# HDSC_HC32F460PEHB register map
Vendor: HDSC Co.,Ltd.; Series: ARMCM4; File version: 1.0
CPU: CM4 r0p1, little endian, MPU, FPU, 4 interrupt priority bits
Registers are 32-bit, read-write, reset 0x0 unless marked. A register's access mark holds for its fields unless they carry their own. Offsets are from the block's base; [hi:lo] are bit positions; 'fields as' and 'values as' point back to an identical list.

## SRAMC
Base 0x40050800
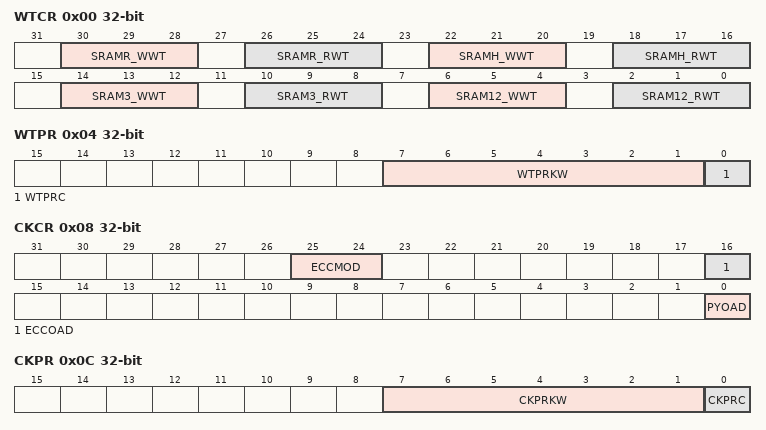
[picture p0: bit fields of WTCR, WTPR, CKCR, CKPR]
0x00 WTCR
  [30:28] SRAMR_WWT, [26:24] SRAMR_RWT, [22:20] SRAMH_WWT, [18:16] SRAMH_RWT, [14:12] SRAM3_WWT, [10:8] SRAM3_RWT, [6:4] SRAM12_WWT, [2:0] SRAM12_RWT
0x04 WTPR
  [7:1] WTPRKW, [0] WTPRC
0x08 CKCR
  [25:24] ECCMOD, [16] ECCOAD, [0] PYOAD
0x0C CKPR
  [7:1] CKPRKW, [0] CKPRC
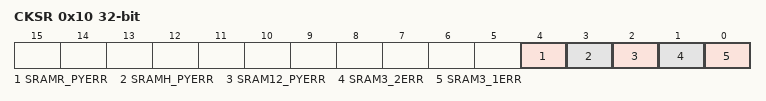
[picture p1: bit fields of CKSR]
0x10 CKSR
  [4] SRAMR_PYERR, [3] SRAMH_PYERR, [2] SRAM12_PYERR, [1] SRAM3_2ERR, [0] SRAM3_1ERR

## SWDT
Base 0x40049400
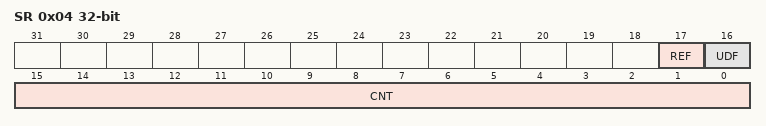
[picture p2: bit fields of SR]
0x04 SR ro
  [17] REF rw, [16] UDF rw, [15:0] CNT
0x08 RR ro
  [15:0] RF

## TMR01 — desc TMR0
Base 0x40024000
Same registers: TMR02 0x40024400
0x00 CNTAR
  [15:0] CNTA
0x04 CNTBR
  [15:0] CNTB
0x08 CMPAR reset 0xFFFF
  [15:0] CMPA
0x0C CMPBR reset 0xFFFF
  [15:0] CMPB
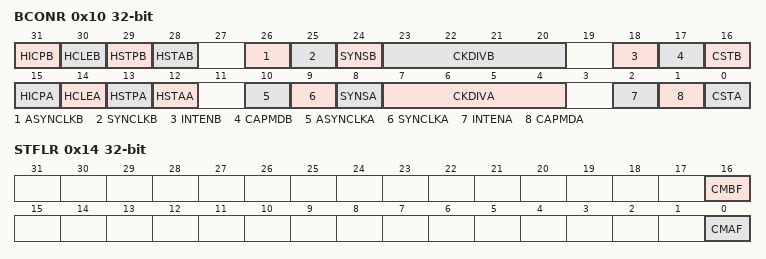
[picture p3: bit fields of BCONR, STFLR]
0x10 BCONR
  [31] HICPB, [30] HCLEB, [29] HSTPB, [28] HSTAB, [26] ASYNCLKB, [25] SYNCLKB, [24] SYNSB, [23:20] CKDIVB, [18] INTENB, [17] CAPMDB, [16] CSTB, [15] HICPA, [14] HCLEA, [13] HSTPA, [12] HSTAA, [10] ASYNCLKA, [9] SYNCLKA, [8] SYNSA, [7:4] CKDIVA, [2] INTENA, [1] CAPMDA, [0] CSTA
0x14 STFLR
  [16] CMBF, [0] CMAF

## TMR41 — desc TMR4
Base 0x40017000
Same registers: TMR42 0x40024800, TMR43 0x40024C00
0x02 OCCRUH 16-bit
0x06 OCCRUL 16-bit
0x0A OCCRVH 16-bit
0x0E OCCRVL 16-bit
0x12 OCCRWH 16-bit
0x16 OCCRWL 16-bit
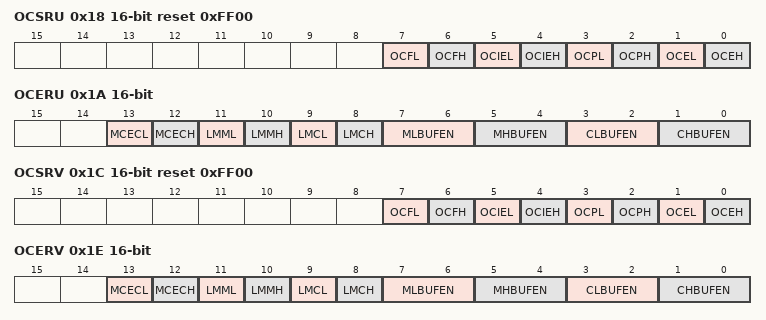
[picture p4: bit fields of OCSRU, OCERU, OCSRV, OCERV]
0x18 OCSRU 16-bit reset 0xFF00
  [7] OCFL, [6] OCFH, [5] OCIEL, [4] OCIEH, [3] OCPL, [2] OCPH, [1] OCEL, [0] OCEH
0x1A OCERU 16-bit
  [13] MCECL, [12] MCECH, [11] LMML, [10] LMMH, [9] LMCL, [8] LMCH, [7:6] MLBUFEN, [5:4] MHBUFEN, [3:2] CLBUFEN, [1:0] CHBUFEN
0x1C OCSRV 16-bit reset 0xFF00
  fields as OCSRU
0x1E OCERV 16-bit
  fields as OCERU
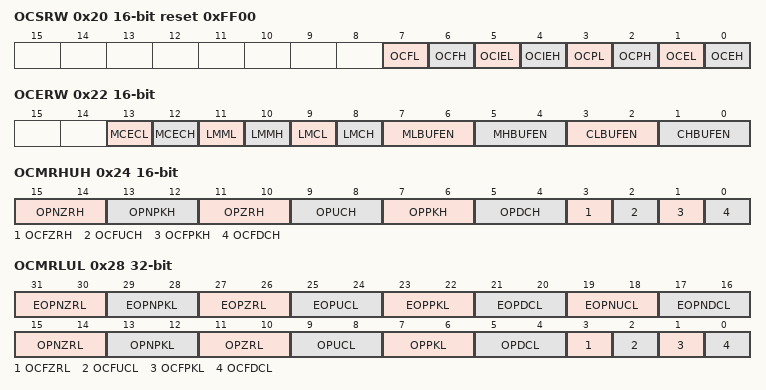
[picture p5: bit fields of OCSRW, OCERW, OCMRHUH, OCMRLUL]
0x20 OCSRW 16-bit reset 0xFF00
  fields as OCSRU
0x22 OCERW 16-bit
  fields as OCERU
0x24 OCMRHUH 16-bit
  [15:14] OPNZRH, [13:12] OPNPKH, [11:10] OPZRH, [9:8] OPUCH, [7:6] OPPKH, [5:4] OPDCH, [3] OCFZRH, [2] OCFUCH, [1] OCFPKH, [0] OCFDCH
0x28 OCMRLUL
  [31:30] EOPNZRL, [29:28] EOPNPKL, [27:26] EOPZRL, [25:24] EOPUCL, [23:22] EOPPKL, [21:20] EOPDCL, [19:18] EOPNUCL, [17:16] EOPNDCL, [15:14] OPNZRL, [13:12] OPNPKL, [11:10] OPZRL, [9:8] OPUCL, [7:6] OPPKL, [5:4] OPDCL, [3] OCFZRL, [2] OCFUCL, [1] OCFPKL, [0] OCFDCL
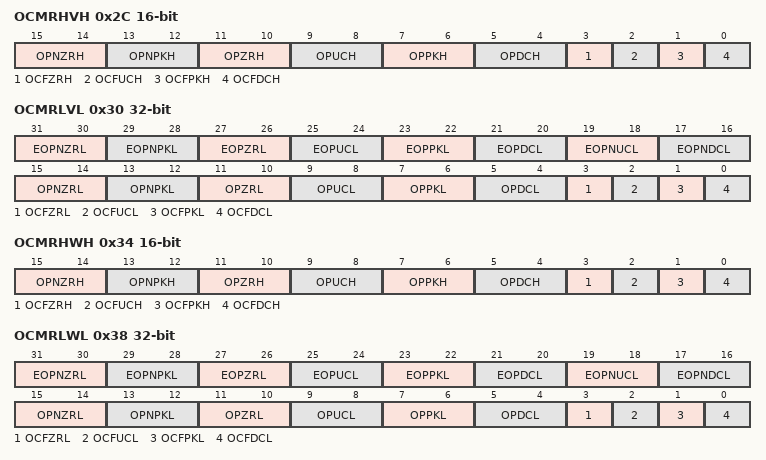
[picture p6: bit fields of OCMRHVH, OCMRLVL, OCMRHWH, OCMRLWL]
0x2C OCMRHVH 16-bit
  fields as OCMRHUH
0x30 OCMRLVL
  fields as OCMRLUL
0x34 OCMRHWH 16-bit
  fields as OCMRHUH
0x38 OCMRLWL
  fields as OCMRLUL
0x42 CPSR 16-bit reset 0xFFFF
0x46 CNTR 16-bit
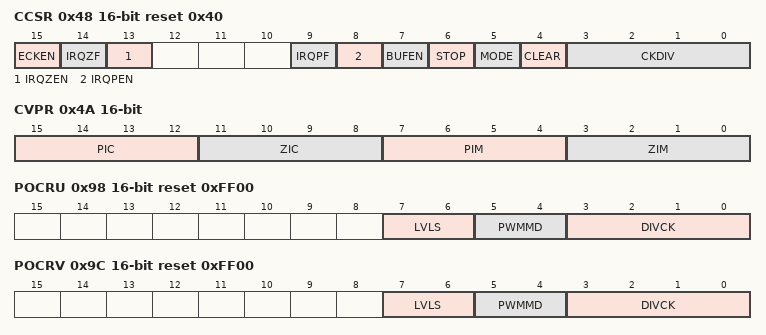
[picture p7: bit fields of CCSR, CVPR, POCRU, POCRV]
0x48 CCSR 16-bit reset 0x40
  [15] ECKEN, [14] IRQZF, [13] IRQZEN, [9] IRQPF, [8] IRQPEN, [7] BUFEN, [6] STOP, [5] MODE, [4] CLEAR, [3:0] CKDIV
0x4A CVPR 16-bit
  [15:12] PIC ro, [11:8] ZIC ro, [7:4] PIM, [3:0] ZIM
0x82 PFSRU 16-bit
0x84 PDARU 16-bit
0x86 PDBRU 16-bit
0x8A PFSRV 16-bit
0x8C PDARV 16-bit
0x8E PDBRV 16-bit
0x92 PFSRW 16-bit
0x94 PDARW 16-bit
0x96 PDBRW 16-bit
0x98 POCRU 16-bit reset 0xFF00
  [7:6] LVLS, [5:4] PWMMD, [3:0] DIVCK
0x9C POCRV 16-bit reset 0xFF00
  [7:6] LVLS, [5:4] PWMMD, [3:0] DIVCK
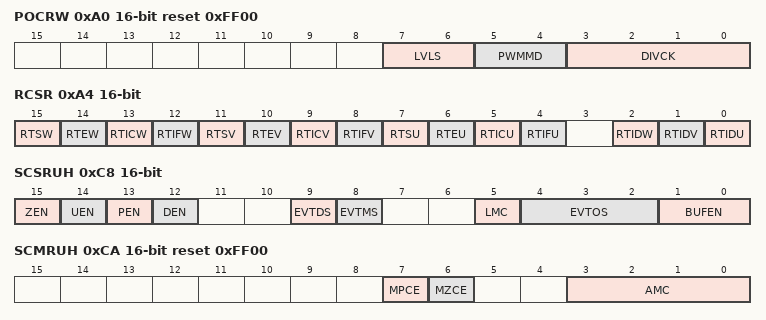
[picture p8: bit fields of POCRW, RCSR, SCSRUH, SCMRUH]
0xA0 POCRW 16-bit reset 0xFF00
  [7:6] LVLS, [5:4] PWMMD, [3:0] DIVCK
0xA4 RCSR 16-bit
  [15] RTSW, [14] RTEW, [13] RTICW, [12] RTIFW ro, [11] RTSV, [10] RTEV, [9] RTICV, [8] RTIFV ro, [7] RTSU, [6] RTEU, [5] RTICU, [4] RTIFU ro, [2] RTIDW, [1] RTIDV, [0] RTIDU
0xB2 SCCRUH 16-bit
0xB6 SCCRUL 16-bit
0xBA SCCRVH 16-bit
0xBE SCCRVL 16-bit
0xC2 SCCRWH 16-bit
0xC6 SCCRWL 16-bit
0xC8 SCSRUH 16-bit
  [15] ZEN, [14] UEN, [13] PEN, [12] DEN, [9] EVTDS, [8] EVTMS, [5] LMC, [4:2] EVTOS, [1:0] BUFEN
0xCA SCMRUH 16-bit reset 0xFF00
  [7] MPCE, [6] MZCE, [3:0] AMC
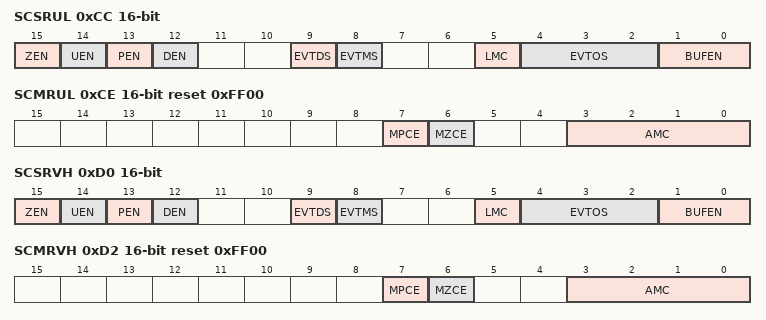
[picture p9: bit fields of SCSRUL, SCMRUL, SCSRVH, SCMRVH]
0xCC SCSRUL 16-bit
  fields as SCSRUH
0xCE SCMRUL 16-bit reset 0xFF00
  [7] MPCE, [6] MZCE, [3:0] AMC
0xD0 SCSRVH 16-bit
  fields as SCSRUH
0xD2 SCMRVH 16-bit reset 0xFF00
  [7] MPCE, [6] MZCE, [3:0] AMC
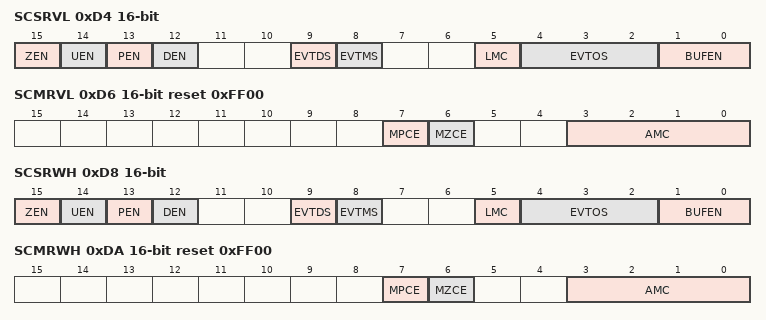
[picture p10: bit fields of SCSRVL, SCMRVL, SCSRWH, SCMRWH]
0xD4 SCSRVL 16-bit
  fields as SCSRUH
0xD6 SCMRVL 16-bit reset 0xFF00
  [7] MPCE, [6] MZCE, [3:0] AMC
0xD8 SCSRWH 16-bit
  fields as SCSRUH
0xDA SCMRWH 16-bit reset 0xFF00
  [7] MPCE, [6] MZCE, [3:0] AMC
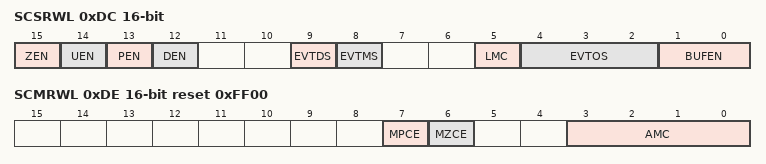
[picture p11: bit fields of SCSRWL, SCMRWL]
0xDC SCSRWL 16-bit
  fields as SCSRUH
0xDE SCMRWL 16-bit reset 0xFF00
  [7] MPCE, [6] MZCE, [3:0] AMC
0xF0 ECSR 16-bit
  [7] HOLD
